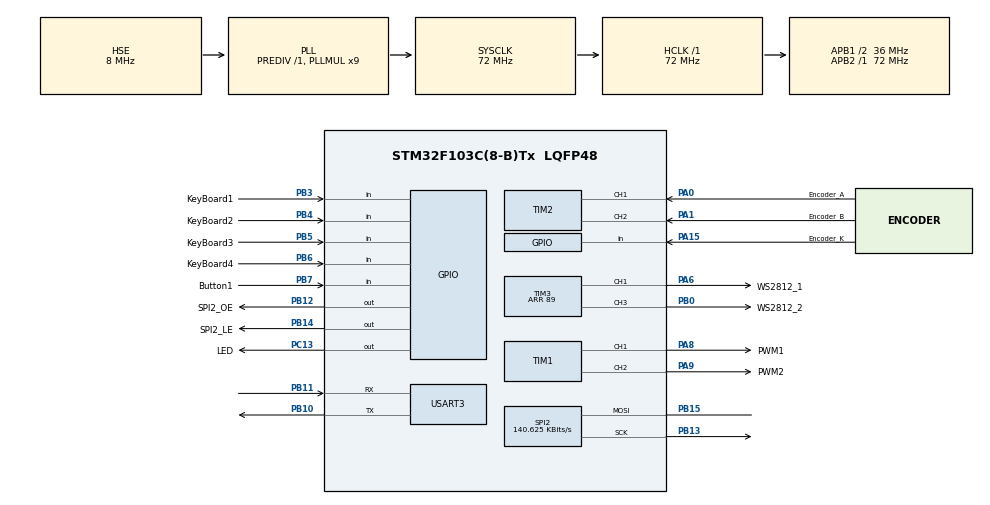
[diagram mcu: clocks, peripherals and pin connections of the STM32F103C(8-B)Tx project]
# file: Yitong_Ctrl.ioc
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Dma.Request0=TIM3_CH1/TRIG
Dma.Request1=TIM3_CH3
Dma.TIM3_CH1/TRIG.0.Direction=DMA_MEMORY_TO_PERIPH
Dma.TIM3_CH1/TRIG.0.Instance=DMA1_Channel6
Dma.TIM3_CH1/TRIG.0.MemDataAlignment=DMA_MDATAALIGN_BYTE
Dma.TIM3_CH1/TRIG.0.MemInc=DMA_MINC_ENABLE
Dma.TIM3_CH1/TRIG.0.Mode=DMA_NORMAL
Dma.TIM3_CH1/TRIG.0.PeriphDataAlignment=DMA_PDATAALIGN_HALFWORD
Dma.TIM3_CH1/TRIG.0.PeriphInc=DMA_PINC_DISABLE
Dma.TIM3_CH1/TRIG.0.Priority=DMA_PRIORITY_LOW
Dma.TIM3_CH3.1.Direction=DMA_MEMORY_TO_PERIPH
Dma.TIM3_CH3.1.Instance=DMA1_Channel2
Dma.TIM3_CH3.1.MemDataAlignment=DMA_MDATAALIGN_BYTE
Dma.TIM3_CH3.1.MemInc=DMA_MINC_ENABLE
Dma.TIM3_CH3.1.Mode=DMA_NORMAL
Dma.TIM3_CH3.1.PeriphDataAlignment=DMA_PDATAALIGN_HALFWORD
Dma.TIM3_CH3.1.PeriphInc=DMA_PINC_DISABLE
Dma.TIM3_CH3.1.Priority=DMA_PRIORITY_LOW
IWDG.Prescaler=IWDG_PRESCALER_32
IWDG.Reload=3000
Mcu.Family=STM32F1
Mcu.Name=STM32F103C(8-B)Tx
Mcu.Package=LQFP48
NVIC.DMA1_Channel2_IRQn=true\:0\:0\:false\:false\:true\:false\:true\:true
NVIC.DMA1_Channel6_IRQn=true\:0\:0\:false\:false\:true\:false\:true\:true
NVIC.PriorityGroup=NVIC_PRIORITYGROUP_4
NVIC.USART3_IRQn=true\:0\:0\:false\:false\:true\:true\:true\:true
PA0-WKUP.GPIO_Label=Encoder_A
PA0-WKUP.Signal=S_TIM2_CH1_ETR
PA1.GPIO_Label=Encoder_B
PA1.Signal=S_TIM2_CH2
PA13.Mode=Serial_Wire
PA13.Signal=SYS_JTMS-SWDIO
PA14.Mode=Serial_Wire
PA14.Signal=SYS_JTCK-SWCLK
PA15.GPIO_Label=Encoder_K
PA15.Signal=GPIO_Input
PA6.GPIO_Label=WS2812_1
PA6.GPIO_Speed=GPIO_SPEED_FREQ_HIGH
PA6.Signal=S_TIM3_CH1
PA8.GPIO_Label=PWM1
PA8.Signal=S_TIM1_CH1
PA9.GPIO_Label=PWM2
PA9.Signal=S_TIM1_CH2
PB0.GPIO_Label=WS2812_2
PB0.GPIO_Speed=GPIO_SPEED_FREQ_HIGH
PB0.Signal=S_TIM3_CH3
PB10.Mode=Asynchronous
PB10.Signal=USART3_TX
PB11.Mode=Asynchronous
PB11.Signal=USART3_RX
PB12.GPIO_Label=SPI2_OE
PB12.Signal=GPIO_Output
PB13.Mode=Simplex_Bidirectional_Master
PB13.Signal=SPI2_SCK
PB14.GPIO_Label=SPI2_LE
PB14.Signal=GPIO_Output
PB15.Mode=Simplex_Bidirectional_Master
PB15.Signal=SPI2_MOSI
PB3.GPIO_Label=KeyBoard1
PB3.Signal=GPIO_Input
PB4.GPIO_Label=KeyBoard2
PB4.Signal=GPIO_Input
PB5.GPIO_Label=KeyBoard3
PB5.Signal=GPIO_Input
PB6.GPIO_Label=KeyBoard4
PB6.Signal=GPIO_Input
PB7.GPIO_Label=Button1
PB7.Signal=GPIO_Input
PC13-TAMPER-RTC.GPIO_Label=LED
PC13-TAMPER-RTC.Signal=GPIO_Output
PD0-OSC_IN.Mode=HSE-External-Oscillator
PD0-OSC_IN.Signal=RCC_OSC_IN
PD1-OSC_OUT.Mode=HSE-External-Oscillator
PD1-OSC_OUT.Signal=RCC_OSC_OUT
ProjectManager.HeapSize=0x200
ProjectManager.StackSize=0x400
ProjectManager.TargetToolchain=MDK-ARM V5.32
RCC.AHBFreq_Value=72000000
RCC.APB1CLKDivider=RCC_HCLK_DIV2
RCC.APB1Freq_Value=36000000
RCC.APB1TimFreq_Value=72000000
RCC.APB2Freq_Value=72000000
RCC.APB2TimFreq_Value=72000000
RCC.HCLKFreq_Value=72000000
RCC.PLLMUL=RCC_PLL_MUL9
RCC.PLLSourceVirtual=RCC_PLLSOURCE_HSE
RCC.SYSCLKFreq_VALUE=72000000
RCC.SYSCLKSource=RCC_SYSCLKSOURCE_PLLCLK
RCC.USBFreq_Value=72000000
SH.S_TIM1_CH1.0=TIM1_CH1,PWM Generation1 CH1
SH.S_TIM1_CH2.0=TIM1_CH2,PWM Generation2 CH2
SH.S_TIM2_CH1_ETR.0=TIM2_CH1,Encoder_Interface
SH.S_TIM2_CH2.0=TIM2_CH2,Encoder_Interface
SH.S_TIM3_CH1.0=TIM3_CH1,PWM Generation1 CH1
SH.S_TIM3_CH3.0=TIM3_CH3,PWM Generation3 CH3
SPI2.BaudRatePrescaler=SPI_BAUDRATEPRESCALER_256
SPI2.CLKPhase=SPI_PHASE_2EDGE
SPI2.CLKPolarity=SPI_POLARITY_HIGH
SPI2.CalculateBaudRate=140.625 KBits/s
SPI2.Direction=SPI_DIRECTION_1LINE
SPI2.Mode=SPI_MODE_MASTER
SPI2.VirtualType=VM_MASTER
TIM1.Channel-PWM\ Generation1\ CH1=TIM_CHANNEL_1
TIM1.Channel-PWM\ Generation2\ CH2=TIM_CHANNEL_2
TIM2.AutoReloadPreload=TIM_AUTORELOAD_PRELOAD_ENABLE
TIM2.IC1Filter=9
TIM3.AutoReloadPreload=TIM_AUTORELOAD_PRELOAD_ENABLE
TIM3.Channel-PWM\ Generation1\ CH1=TIM_CHANNEL_1
TIM3.Channel-PWM\ Generation3\ CH3=TIM_CHANNEL_3
TIM3.Period=89
USART3.VirtualMode=VM_ASYNC
VP_IWDG_VS_IWDG.Mode=IWDG_Activate
VP_TIM1_VS_ClockSourceINT.Mode=Internal
VP_TIM3_VS_ClockSourceINT.Mode=Internal
board=custom

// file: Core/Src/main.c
/* USER CODE BEGIN Header */
/**
  ******************************************************************************
  * @file           : main.c
  * @brief          : Main program body
  ******************************************************************************
  */
/* USER CODE END Header */
#include "main.h"
#include "dma.h"
#include "iwdg.h"
#include "spi.h"
#include "tim.h"
#include "usart.h"
#include "gpio.h"

/* USER CODE BEGIN Includes */
#include "MainTask.h"
/* USER CODE END Includes */

void SystemClock_Config(void);

int main(void)
{
  HAL_Init();
  SystemClock_Config();

  MX_GPIO_Init();
  MX_DMA_Init();
  MX_TIM3_Init();
  /* 中文注释：控台数码管按原理图继续使用SPI2：PB13时钟、PB15数据，PB14单独锁存。 */
  MX_SPI2_Init();
  MX_TIM1_Init();
  MX_TIM2_Init();
  /* 中文注释：控台与主板仅使用USART3/PB10/PB11，不再初始化旧模板USART2。 */
  MX_USART3_UART_Init();
  MX_IWDG_Init();

  Main_Init();

  while (1)
  {
    Main_Task();
  }
}

void SystemClock_Config(void)
{
  RCC_OscInitTypeDef RCC_OscInitStruct = {0};
  RCC_ClkInitTypeDef RCC_ClkInitStruct = {0};

  /* 中文注释：控台实物晶振为8MHz，原理图25MHz标注错误；8MHz×9保持72MHz系统时钟。 */
  RCC_OscInitStruct.OscillatorType = RCC_OSCILLATORTYPE_LSI|RCC_OSCILLATORTYPE_HSE;
  RCC_OscInitStruct.HSEState = RCC_HSE_ON;
  RCC_OscInitStruct.HSEPredivValue = RCC_HSE_PREDIV_DIV1;
  RCC_OscInitStruct.HSIState = RCC_HSI_ON;
  RCC_OscInitStruct.LSIState = RCC_LSI_ON;
  RCC_OscInitStruct.PLL.PLLState = RCC_PLL_ON;
  RCC_OscInitStruct.PLL.PLLSource = RCC_PLLSOURCE_HSE;
  RCC_OscInitStruct.PLL.PLLMUL = RCC_PLL_MUL9;
  if (HAL_RCC_OscConfig(&RCC_OscInitStruct) != HAL_OK)
  {
    Error_Handler();
  }

  RCC_ClkInitStruct.ClockType = RCC_CLOCKTYPE_HCLK|RCC_CLOCKTYPE_SYSCLK
                              |RCC_CLOCKTYPE_PCLK1|RCC_CLOCKTYPE_PCLK2;
  RCC_ClkInitStruct.SYSCLKSource = RCC_SYSCLKSOURCE_PLLCLK;
  RCC_ClkInitStruct.AHBCLKDivider = RCC_SYSCLK_DIV1;
  RCC_ClkInitStruct.APB1CLKDivider = RCC_HCLK_DIV2;
  RCC_ClkInitStruct.APB2CLKDivider = RCC_HCLK_DIV1;

  if (HAL_RCC_ClockConfig(&RCC_ClkInitStruct, FLASH_LATENCY_2) != HAL_OK)
  {
    Error_Handler();
  }
}

void Error_Handler(void)
{
  __disable_irq();
  while (1)
  {
  }
}
